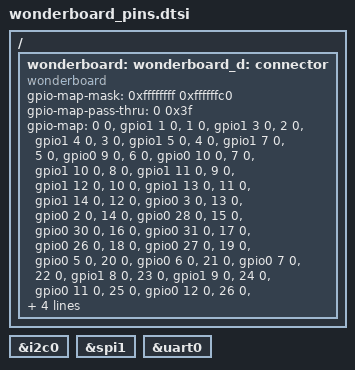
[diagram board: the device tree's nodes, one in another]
/ {
    wonderboard: connector {
        compatible = "wonderboard";
        #gpio-cells = <2>; // 2 for nrf52
        gpio-map-mask = <0xffffffff 0xffffffc0>;
        gpio-map-pass-thru = <0 0x3f>; 
        gpio-map
            = <0 0 &gpio1 1 0>   
            , <1 0 &gpio1 3 0>     
            , <2 0 &gpio1 4 0>     
            , <3 0 &gpio1 5 0>
            , <4 0 &gpio1 7 0>
            , <5 0 &gpio0 9 0>     
            , <6 0 &gpio0 10 0>
            , <7 0 &gpio1 10 0>     
            , <8 0 &gpio1 11 0>     
            , <9 0 &gpio1 12 0>   
            , <10 0 &gpio1 13 0>  
            , <11 0 &gpio1 14 0>  
            , <12 0 &gpio0 3 0>   
            , <13 0 &gpio0 2 0>   
            , <14 0 &gpio0 28 0> 
            , <15 0 &gpio0 30 0> 
            , <16 0 &gpio0 31 0> 
            , <17 0 &gpio0 26 0> 
            , <18 0 &gpio0 27 0> 
            , <19 0 &gpio0 5 0> 
            , <20 0 &gpio0 6 0>
            , <21 0 &gpio0 7 0>
            , <22 0 &gpio1 8 0>
            , <23 0 &gpio1 9 0>
            , <24 0 &gpio0 11 0> 
            , <25 0 &gpio0 12 0>
            , <26 0 &gpio0 14 0>
            , <27 0 &gpio0 16 0>
            , <28 0 &gpio0 15 0>
            , <29 0 &gpio0 13 0> 
            , <30 0 &gpio0 19 0>
            , <31 0 &gpio0 21 0>
            , <32 0 &gpio0 22 0>
            , <33 0 &gpio0 23 0>
            ;
    };
};
    

wonderboard_d: &wonderboard {};
wonderboard_i2c: &i2c0 {};
wonderboard_spi: &spi1 {};
wonderboard_serial: &uart0 {}; 
